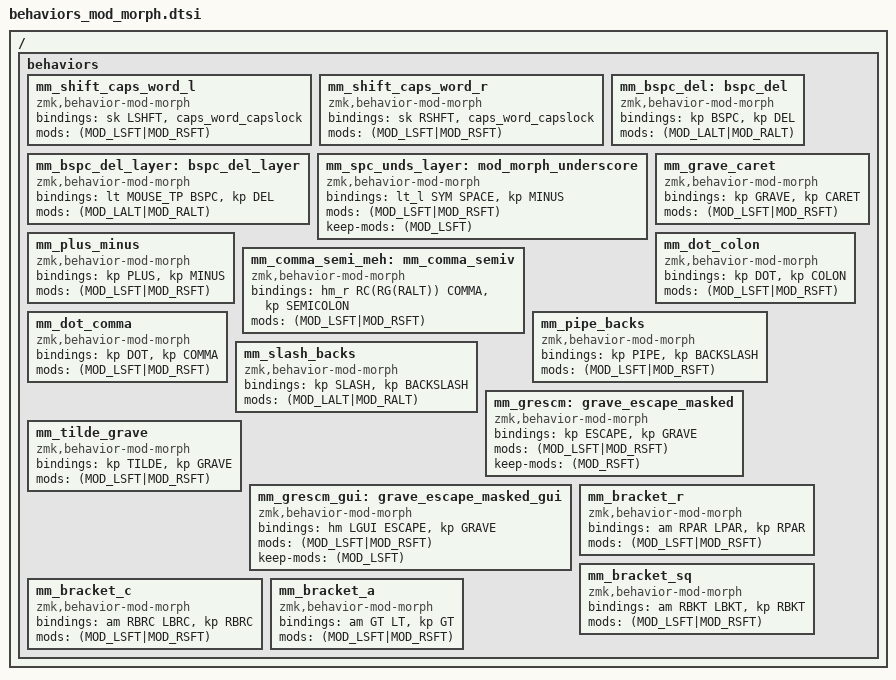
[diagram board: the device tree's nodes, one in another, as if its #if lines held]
// Make sure settings.dtsi is included before this file

// Define layer numbers
#define BASE 0
#define SYM 1
#define NAV 2
#define NUM 3
#define FUNC 4
#define KEYB 5
#define FLASH 6
#ifdef HAS_MOUSE_TP
#define MOUSE_TP 7
#define MOUSE_TP_SET 8
#endif
/ {

    behaviors {

        /*
         * Sticky shift + Caps Word
         *
         * Usage: &mm_shift_caps_word_l or &mm_shift_caps_word_r
         * Tap: Sticky shift
         * HMR-Shift-Tap: Caps Word
         * Double Tap: Caps Word
         *   - The first tap activates sticky shift mod
         *   - The second tap is now a shift + press, which activates
         *     the mod morph
         * Hold: Shift
         *
         * Credits to urob for this genius combo.
         */
        mm_shift_caps_word_l: mm_shift_caps_word_l {
            compatible = "zmk,behavior-mod-morph";
            #binding-cells = <0>;

            #ifdef HAS_CAPSLOCK
                bindings = <&sk LSHFT>, <&caps_word_capslock>;
            #else
                bindings = <&sk LSHFT>, <&caps_word>;
            #endif

            mods = <(MOD_LSFT|MOD_RSFT)>;
        };

        mm_shift_caps_word_r: mm_shift_caps_word_r {
            compatible = "zmk,behavior-mod-morph";
            #binding-cells = <0>;

            #ifdef HAS_CAPSLOCK
                bindings = <&sk RSHFT>, <&caps_word_capslock>;
            #else
                bindings = <&sk RSHFT>, <&caps_word>;
            #endif

            mods = <(MOD_LSFT|MOD_RSFT)>;
        };

        /*
         * Ctrled Backspace deletes
         *
         * Usage: &mm_bspc_del
         * Tap: Backfspace
         * Ctrl-Tap: Delete
         */
        mm_bspc_del: bspc_del {
            compatible = "zmk,behavior-mod-morph";
            #binding-cells = <0>;
            bindings = <&kp BSPC>, <&kp DEL>;
            mods = <(MOD_LALT|MOD_RALT)>;
        };

        /*
         * Ctrled Backspace deletes + Layer Tap
         *
         * Usage: &mm_bspc_del_layer
         * Tap: Backspace
         * Alt-Tap: Delete
         * Hold: Switch layer
         */
        mm_bspc_del_layer: bspc_del_layer {
            compatible = "zmk,behavior-mod-morph";
            #binding-cells = <0>;
            #ifdef HAS_MOUSE_TP
                bindings = <&lt MOUSE_TP BSPC>, <&kp DEL>;
            #else
                bindings = <&lt NAV BSPC>, <&kp DEL>;
            #endif
            mods = <(MOD_LALT|MOD_RALT)>;
        };

        /*
         * Shifted Space underscores + Layer Tap
         *
         * Usage: &mm_spc_unds_layer
         * Tap: Space
         * LShift-Tap: -
         * RShift-Tap: _
         * Hold: Switch layer
         */
        mm_spc_unds_layer: mod_morph_underscore {
            compatible = "zmk,behavior-mod-morph";
            #binding-cells = <0>;
            bindings = <&lt_l SYM SPACE>, <&kp MINUS>;
            mods = <(MOD_LSFT|MOD_RSFT)>;
            keep-mods = <(MOD_LSFT)>;
        };

        /*
         * Shifted grave types caret (^)
         *
         * Usage: &mm_grave_caret
         * Tap: `
         * Shift-Tap: ^
         */
        mm_grave_caret: mm_grave_caret {
            compatible = "zmk,behavior-mod-morph";
            #binding-cells = <0>;
            bindings = <&kp GRAVE>, <&kp CARET>;
            mods = <(MOD_LSFT|MOD_RSFT)>;
        };

        /*
         * Shifted plus types minus (-)
         *
         * Usage: &mm_plus_minus
         * Tap: `
         * Shift-Tap: ^
         */
        mm_plus_minus: mm_plus_minus {
            compatible = "zmk,behavior-mod-morph";
            #binding-cells = <0>;
            bindings = <&kp PLUS>, <&kp MINUS>;
            mods = <(MOD_LSFT|MOD_RSFT)>;
        };

        /*
         * Shifted comma types semicoln
         *
         * Usage: &mm_comma_semi
         * Tap: ,
         * Shift-Tap: ;
         * Hold: MEH
         */
        mm_comma_semi_meh: mm_comma_semiv {
            compatible = "zmk,behavior-mod-morph";
            #binding-cells = <0>;
            bindings = <&hm_r RC(RG(RALT)) COMMA>, <&kp SEMICOLON>;
            mods = <(MOD_LSFT|MOD_RSFT)>;
        };

        /*
         * Shifted dot types colon
         *
         * Usage: &mm_dot_colon
         * Tap: .
         * Shift-Tap: :
         */
        mm_dot_colon: mm_dot_colon {
            compatible = "zmk,behavior-mod-morph";
            #binding-cells = <0>;
            bindings = <&kp DOT>, <&kp COLON>;
            mods = <(MOD_LSFT|MOD_RSFT)>;
        };

        /*
         * Shifted dot types comma
         *
         * Usage: &mm_dot_comma
         * Tap: .
         * Shift-Tap: ,
         */
        mm_dot_comma: mm_dot_comma {
            compatible = "zmk,behavior-mod-morph";
            #binding-cells = <0>;
            bindings = <&kp DOT>, <&kp COMMA>;
            mods = <(MOD_LSFT|MOD_RSFT)>;
        };

        /*
         * Shifted pipe types backs
         *
         * Usage: &mm_pipe_backs
         * Tap: |
         * Shift-Tap: \
         */
        mm_pipe_backs: mm_pipe_backs {
            compatible = "zmk,behavior-mod-morph";
            #binding-cells = <0>;
            bindings = <&kp PIPE>, <&kp BACKSLASH>;
            mods = <(MOD_LSFT|MOD_RSFT)>;
        };

        /*
         * Alted slash types backslash
         *
         * Usage: &mm_slash_backs
         * Tap: /
         * Alt-Tap: \
         */
        mm_slash_backs: mm_slash_backs {
            compatible = "zmk,behavior-mod-morph";
            #binding-cells = <0>;
            bindings = <&kp SLASH>, <&kp BACKSLASH>;
            mods = <(MOD_LALT|MOD_RALT)>;
        };

        /*
         * Grave Escape
         *
         * Usage: &grave_escape_masked
         * Tap: Escape
         * LShift-Tap: `
         * RShift-Tap: ~
         */
        mm_grescm: grave_escape_masked {
            compatible = "zmk,behavior-mod-morph";
            #binding-cells = <0>;
            bindings = <&kp ESCAPE>, <&kp GRAVE>;
            mods = <(MOD_LSFT|MOD_RSFT)>;
            keep-mods = <(MOD_RSFT)>;
        };

        /*
         * Tilde Grave
         *
         * Usage: &mm_tilde_grave
         * Tap: ~
         * Shift-Tap: `
         */
        mm_tilde_grave: mm_tilde_grave {
            compatible = "zmk,behavior-mod-morph";
            #binding-cells = <0>;
            bindings = <&kp TILDE>, <&kp GRAVE>;
            mods = <(MOD_LSFT|MOD_RSFT)>;
        };

        /*
         * Grave Escape + GUI
         *
         * Usage: &grescm_gui
         * Tap: Escape
         * LShift-Tap: ~
         * RShift-Tap: `
         * Hold: GUI
         */
        mm_grescm_gui: grave_escape_masked_gui {
            compatible = "zmk,behavior-mod-morph";
            #binding-cells = <0>;
            bindings = <&hm LGUI ESCAPE>, <&kp GRAVE>;
            mods = <(MOD_LSFT|MOD_RSFT)>;
            keep-mods = <(MOD_LSFT)>;
        };

        /*
         * Round Bracket
         *
         * Usage: &mm_bracket_r
         * Tap: (
         * Shift-Tap: )
         * Hold: )
         */
        mm_bracket_r: mm_bracket_r {
            compatible = "zmk,behavior-mod-morph";
            #binding-cells = <0>;
            bindings = <&am RPAR LPAR>, <&kp RPAR>;
            mods = <(MOD_LSFT|MOD_RSFT)>;
        };

        /*
         * Square Bracket
         *
         * Usage: &mm_bracket_sq
         * Tap: [
         * Shift-Tap: ]
         * Hold: ]
         */
        mm_bracket_sq: mm_bracket_sq {
            compatible = "zmk,behavior-mod-morph";
            #binding-cells = <0>;
            bindings = <&am RBKT LBKT>, <&kp RBKT>;
            mods = <(MOD_LSFT|MOD_RSFT)>;
        };

        /*
         * Curly Bracket
         *
         * Usage: &mm_bracket_c
         * Tap: {
         * Shift-Tap: }
         * Hold: }
         */
        mm_bracket_c: mm_bracket_c {
            compatible = "zmk,behavior-mod-morph";
            #binding-cells = <0>;
            bindings = <&am RBRC LBRC>, <&kp RBRC>;
            mods = <(MOD_LSFT|MOD_RSFT)>;
        };

        /*
         * Angled Bracket
         *
         * Usage: &mm_bracket_a
         * Tap: <
         * Shift-Tap: >
         * Hold: >
         */
        mm_bracket_a: mm_bracket_a {
            compatible = "zmk,behavior-mod-morph";
            #binding-cells = <0>;
            bindings = <&am GT LT>, <&kp GT>;
            mods = <(MOD_LSFT|MOD_RSFT)>;
        };
    };
};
